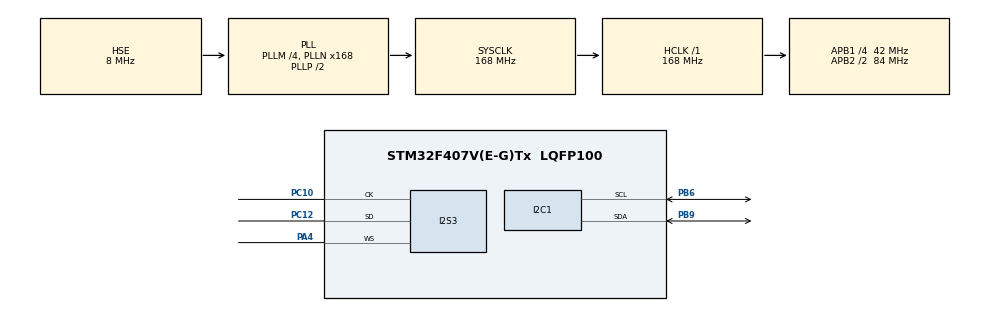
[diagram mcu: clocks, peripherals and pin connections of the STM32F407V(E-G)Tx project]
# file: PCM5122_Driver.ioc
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Dma.Request0=SPI3_TX
Dma.SPI3_TX.0.Direction=DMA_MEMORY_TO_PERIPH
Dma.SPI3_TX.0.FIFOMode=DMA_FIFOMODE_DISABLE
Dma.SPI3_TX.0.Instance=DMA1_Stream7
Dma.SPI3_TX.0.MemDataAlignment=DMA_MDATAALIGN_HALFWORD
Dma.SPI3_TX.0.MemInc=DMA_MINC_ENABLE
Dma.SPI3_TX.0.Mode=DMA_CIRCULAR
Dma.SPI3_TX.0.PeriphDataAlignment=DMA_PDATAALIGN_HALFWORD
Dma.SPI3_TX.0.PeriphInc=DMA_PINC_DISABLE
Dma.SPI3_TX.0.Priority=DMA_PRIORITY_LOW
I2S3.AudioFreq=I2S_AUDIOFREQ_48K
I2S3.ErrorAudioFreq=-1.35 %
I2S3.FullDuplexMode=I2S_FULLDUPLEXMODE_DISABLE
I2S3.Instance=SPI$Index
I2S3.RealAudioFreq=47.348 KHz
I2S3.VirtualMode=I2S_MODE_MASTER
Mcu.Family=STM32F4
Mcu.Name=STM32F407V(E-G)Tx
Mcu.Package=LQFP100
NVIC.DMA1_Stream7_IRQn=true\:2\:0\:true\:false\:true\:false\:true
NVIC.PriorityGroup=NVIC_PRIORITYGROUP_4
PA13.Mode=Serial_Wire
PA13.Signal=SYS_JTMS-SWDIO
PA14.Mode=Serial_Wire
PA14.Signal=SYS_JTCK-SWCLK
PA4.GPIO_Speed=GPIO_SPEED_FREQ_VERY_HIGH
PA4.Mode=Half_Duplex_Master
PA4.Signal=I2S3_WS
PB6.Mode=I2C
PB6.Signal=I2C1_SCL
PB9.Mode=I2C
PB9.Signal=I2C1_SDA
PC10.GPIO_Speed=GPIO_SPEED_FREQ_VERY_HIGH
PC10.Mode=Half_Duplex_Master
PC10.Signal=I2S3_CK
PC12.GPIO_Speed=GPIO_SPEED_FREQ_VERY_HIGH
PC12.Mode=Half_Duplex_Master
PC12.Signal=I2S3_SD
PH0-OSC_IN.Mode=HSE-External-Clock-Source
PH0-OSC_IN.Signal=RCC_OSC_IN
PH1-OSC_OUT.Mode=HSE-External-Clock-Source
PH1-OSC_OUT.Signal=RCC_OSC_OUT
ProjectManager.HeapSize=0x200
ProjectManager.StackSize=0x400
ProjectManager.TargetToolchain=STM32CubeIDE
RCC.48MHZClocksFreq_Value=84000000
RCC.AHBFreq_Value=168000000
RCC.APB1CLKDivider=RCC_HCLK_DIV4
RCC.APB1Freq_Value=42000000
RCC.APB1TimFreq_Value=84000000
RCC.APB2CLKDivider=RCC_HCLK_DIV2
RCC.APB2Freq_Value=84000000
RCC.APB2TimFreq_Value=168000000
RCC.CortexFreq_Value=168000000
RCC.HCLKFreq_Value=168000000
RCC.HSE_VALUE=8000000
RCC.HSI_VALUE=16000000
RCC.LSE_VALUE=32768
RCC.PLLI2SN=50
RCC.PLLM=4
RCC.PLLN=168
RCC.PLLSourceVirtual=RCC_PLLSOURCE_HSE
RCC.SYSCLKFreq_VALUE=168000000
RCC.SYSCLKSource=RCC_SYSCLKSOURCE_PLLCLK
RCC.VCOOutputFreq_Value=336000000
board=custom

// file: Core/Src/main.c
/* USER CODE BEGIN Header */
/**
  ******************************************************************************
  * @file           : main.c
  * @brief          : Main program body
  ******************************************************************************
  * @attention
  *
  * <h2><center>&copy; Copyright (c) 2021 STMicroelectronics.
  * All rights reserved.</center></h2>
  *
  * This software component is licensed by ST under BSD 3-Clause license,
  * the "License"; You may not use this file except in compliance with the
  * License. You may obtain a copy of the License at:
  *                        opensource.org/licenses/BSD-3-Clause
  *
  ******************************************************************************
  */
/* USER CODE END Header */
#include "main.h"
#include "dma.h"
#include "i2c.h"
#include "i2s.h"
#include "gpio.h"

/* USER CODE BEGIN Includes */
#include "PCM5122.h"
/* USER CODE END Includes */

void SystemClock_Config(void);

int main(void)
{

  /* MCU Configuration--------------------------------------------------------*/

  /* Reset of all peripherals, Initializes the Flash interface and the Systick. */
  HAL_Init();

  /* Configure the system clock */
  SystemClock_Config();

  /* Initialize all configured peripherals */
  MX_GPIO_Init();
  MX_DMA_Init();
  MX_I2S3_Init();
  MX_I2C1_Init();

  /* Infinite loop */
  /* USER CODE BEGIN WHILE */
  PCM5122_Setup();
  PCM5122_PlaySineWaveSample(25);

  while (1)
  {
    /* USER CODE END WHILE */

  }
}

void SystemClock_Config(void)
{
  RCC_OscInitTypeDef RCC_OscInitStruct = {0};
  RCC_ClkInitTypeDef RCC_ClkInitStruct = {0};

  /** Configure the main internal regulator output voltage
  */
  __HAL_RCC_PWR_CLK_ENABLE();
  __HAL_PWR_VOLTAGESCALING_CONFIG(PWR_REGULATOR_VOLTAGE_SCALE1);
  /** Initializes the RCC Oscillators according to the specified parameters
  * in the RCC_OscInitTypeDef structure.
  */
  RCC_OscInitStruct.OscillatorType = RCC_OSCILLATORTYPE_HSE;
  RCC_OscInitStruct.HSEState = RCC_HSE_BYPASS;
  RCC_OscInitStruct.PLL.PLLState = RCC_PLL_ON;
  RCC_OscInitStruct.PLL.PLLSource = RCC_PLLSOURCE_HSE;
  RCC_OscInitStruct.PLL.PLLM = 4;
  RCC_OscInitStruct.PLL.PLLN = 168;
  RCC_OscInitStruct.PLL.PLLP = RCC_PLLP_DIV2;
  RCC_OscInitStruct.PLL.PLLQ = 4;
  if (HAL_RCC_OscConfig(&RCC_OscInitStruct) != HAL_OK)
  {
    Error_Handler();
  }
  /** Initializes the CPU, AHB and APB buses clocks
  */
  RCC_ClkInitStruct.ClockType = RCC_CLOCKTYPE_HCLK|RCC_CLOCKTYPE_SYSCLK
                              |RCC_CLOCKTYPE_PCLK1|RCC_CLOCKTYPE_PCLK2;
  RCC_ClkInitStruct.SYSCLKSource = RCC_SYSCLKSOURCE_PLLCLK;
  RCC_ClkInitStruct.AHBCLKDivider = RCC_SYSCLK_DIV1;
  RCC_ClkInitStruct.APB1CLKDivider = RCC_HCLK_DIV4;
  RCC_ClkInitStruct.APB2CLKDivider = RCC_HCLK_DIV2;

  if (HAL_RCC_ClockConfig(&RCC_ClkInitStruct, FLASH_LATENCY_5) != HAL_OK)
  {
    Error_Handler();
  }
}

void Error_Handler(void)
{
  __disable_irq();
  while (1)
  {
  }
}

/************************ (C) COPYRIGHT STMicroelectronics *****END OF FILE****/
